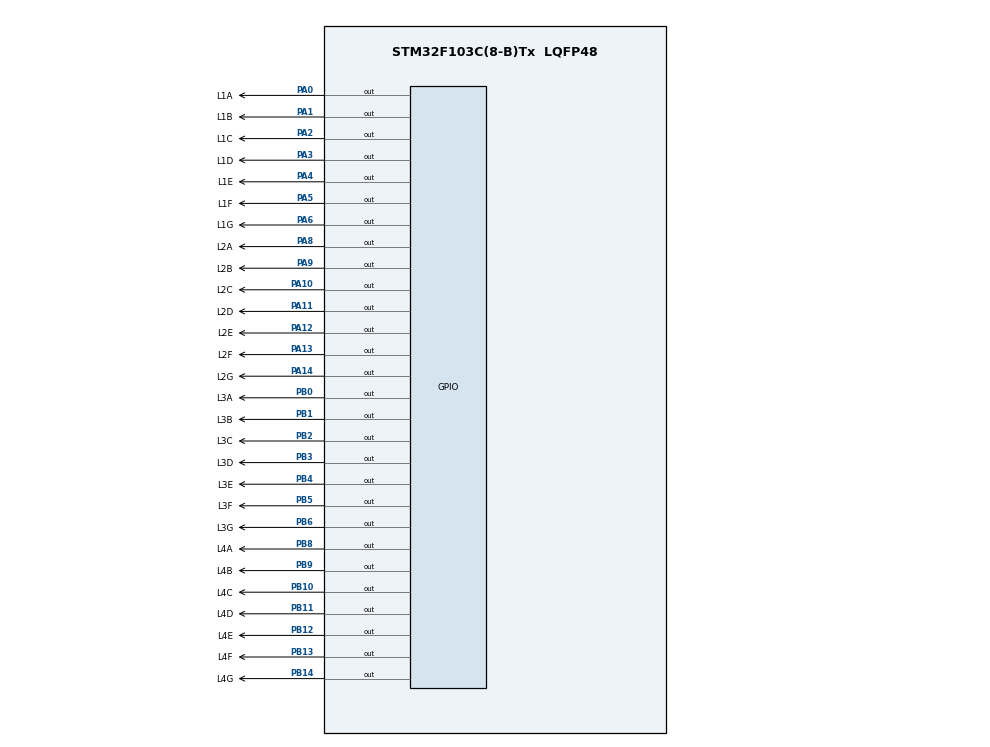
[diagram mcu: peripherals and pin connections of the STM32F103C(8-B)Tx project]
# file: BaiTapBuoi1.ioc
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Mcu.Family=STM32F1
Mcu.Name=STM32F103C(8-B)Tx
Mcu.Package=LQFP48
NVIC.PriorityGroup=NVIC_PRIORITYGROUP_4
PA0-WKUP.GPIO_Label=L1A
PA0-WKUP.Signal=GPIO_Output
PA1.GPIO_Label=L1B
PA1.Signal=GPIO_Output
PA10.GPIO_Label=L2C
PA10.Signal=GPIO_Output
PA11.GPIO_Label=L2D
PA11.Signal=GPIO_Output
PA12.GPIO_Label=L2E
PA12.Signal=GPIO_Output
PA13.GPIO_Label=L2F
PA13.Signal=GPIO_Output
PA14.GPIO_Label=L2G
PA14.Signal=GPIO_Output
PA2.GPIO_Label=L1C
PA2.Signal=GPIO_Output
PA3.GPIO_Label=L1D
PA3.Signal=GPIO_Output
PA4.GPIO_Label=L1E
PA4.Signal=GPIO_Output
PA5.GPIO_Label=L1F
PA5.Signal=GPIO_Output
PA6.GPIO_Label=L1G
PA6.Signal=GPIO_Output
PA8.GPIO_Label=L2A
PA8.Signal=GPIO_Output
PA9.GPIO_Label=L2B
PA9.Signal=GPIO_Output
PB0.GPIO_Label=L3A
PB0.Signal=GPIO_Output
PB1.GPIO_Label=L3B
PB1.Signal=GPIO_Output
PB10.GPIO_Label=L4C
PB10.Signal=GPIO_Output
PB11.GPIO_Label=L4D
PB11.Signal=GPIO_Output
PB12.GPIO_Label=L4E
PB12.Signal=GPIO_Output
PB13.GPIO_Label=L4F
PB13.Signal=GPIO_Output
PB14.GPIO_Label=L4G
PB14.Signal=GPIO_Output
PB2.GPIO_Label=L3C
PB2.Signal=GPIO_Output
PB3.GPIO_Label=L3D
PB3.Signal=GPIO_Output
PB4.GPIO_Label=L3E
PB4.Signal=GPIO_Output
PB5.GPIO_Label=L3F
PB5.Signal=GPIO_Output
PB6.GPIO_Label=L3G
PB6.Signal=GPIO_Output
PB8.GPIO_Label=L4A
PB8.Signal=GPIO_Output
PB9.GPIO_Label=L4B
PB9.Signal=GPIO_Output
ProjectManager.HeapSize=0x200
ProjectManager.StackSize=0x400
ProjectManager.TargetToolchain=MDK-ARM V5.32
RCC.APB1Freq_Value=8000000
RCC.APB2Freq_Value=8000000
VP_SYS_VS_ND.Mode=No_Debug
board=custom

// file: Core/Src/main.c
/* USER CODE BEGIN Header */
/**
  ******************************************************************************
  * @file           : main.c
  * @brief          : Main program body
  ******************************************************************************
  * @attention
  *
  * Copyright (c) 2025 STMicroelectronics.
  * All rights reserved.
  *
  * This software is licensed under terms that can be found in the LICENSE file
  * in the root directory of this software component.
  * If no LICENSE file comes with this software, it is provided AS-IS.
  *
  ******************************************************************************
  */
/* USER CODE END Header */
#include "main.h"

/* USER CODE BEGIN Includes */
#include "myLED.h"
/* USER CODE END Includes */

/* USER CODE BEGIN PV */

uint16_t num = 0;

/* USER CODE END PV */

void SystemClock_Config(void);
static void MX_GPIO_Init(void);

int main(void)
{

  /* MCU Configuration--------------------------------------------------------*/

  /* Reset of all peripherals, Initializes the Flash interface and the Systick. */
  HAL_Init();

  /* Configure the system clock */
  SystemClock_Config();

  /* Initialize all configured peripherals */
  MX_GPIO_Init();

  /* Infinite loop */
  /* USER CODE BEGIN WHILE */
  while (1)
  {
		LED_display(num);
		HAL_Delay(300);
		if(++num == 10000)
		{
			num = 0;
		}
    /* USER CODE END WHILE */

  }
}

void SystemClock_Config(void)
{
  RCC_OscInitTypeDef RCC_OscInitStruct = {0};
  RCC_ClkInitTypeDef RCC_ClkInitStruct = {0};

  /** Initializes the RCC Oscillators according to the specified parameters
  * in the RCC_OscInitTypeDef structure.
  */
  RCC_OscInitStruct.OscillatorType = RCC_OSCILLATORTYPE_HSI;
  RCC_OscInitStruct.HSIState = RCC_HSI_ON;
  RCC_OscInitStruct.HSICalibrationValue = RCC_HSICALIBRATION_DEFAULT;
  RCC_OscInitStruct.PLL.PLLState = RCC_PLL_NONE;
  if (HAL_RCC_OscConfig(&RCC_OscInitStruct) != HAL_OK)
  {
    Error_Handler();
  }

  /** Initializes the CPU, AHB and APB buses clocks
  */
  RCC_ClkInitStruct.ClockType = RCC_CLOCKTYPE_HCLK|RCC_CLOCKTYPE_SYSCLK
                              |RCC_CLOCKTYPE_PCLK1|RCC_CLOCKTYPE_PCLK2;
  RCC_ClkInitStruct.SYSCLKSource = RCC_SYSCLKSOURCE_HSI;
  RCC_ClkInitStruct.AHBCLKDivider = RCC_SYSCLK_DIV1;
  RCC_ClkInitStruct.APB1CLKDivider = RCC_HCLK_DIV1;
  RCC_ClkInitStruct.APB2CLKDivider = RCC_HCLK_DIV1;

  if (HAL_RCC_ClockConfig(&RCC_ClkInitStruct, FLASH_LATENCY_0) != HAL_OK)
  {
    Error_Handler();
  }
}

static void MX_GPIO_Init(void)
{
  GPIO_InitTypeDef GPIO_InitStruct = {0};

  /* GPIO Ports Clock Enable */
  __HAL_RCC_GPIOA_CLK_ENABLE();
  __HAL_RCC_GPIOB_CLK_ENABLE();

  /*Configure GPIO pin Output Level */
  HAL_GPIO_WritePin(GPIOA, L1A_Pin|L1B_Pin|L1C_Pin|L1D_Pin
                          |L1E_Pin|L1F_Pin|L1G_Pin|L2A_Pin
                          |L2B_Pin|L2C_Pin|L2D_Pin|L2E_Pin
                          |L2F_Pin|L2G_Pin, GPIO_PIN_RESET);

  /*Configure GPIO pin Output Level */
  HAL_GPIO_WritePin(GPIOB, L3A_Pin|L3B_Pin|L3C_Pin|L4C_Pin
                          |L4D_Pin|L4E_Pin|L4F_Pin|L4G_Pin
                          |L3D_Pin|L3E_Pin|L3F_Pin|L3G_Pin
                          |L4A_Pin|L4B_Pin, GPIO_PIN_RESET);

  /*Configure GPIO pins : L1A_Pin L1B_Pin L1C_Pin L1D_Pin
                           L1E_Pin L1F_Pin L1G_Pin L2A_Pin
                           L2B_Pin L2C_Pin L2D_Pin L2E_Pin
                           L2F_Pin L2G_Pin */
  GPIO_InitStruct.Pin = L1A_Pin|L1B_Pin|L1C_Pin|L1D_Pin
                          |L1E_Pin|L1F_Pin|L1G_Pin|L2A_Pin
                          |L2B_Pin|L2C_Pin|L2D_Pin|L2E_Pin
                          |L2F_Pin|L2G_Pin;
  GPIO_InitStruct.Mode = GPIO_MODE_OUTPUT_PP;
  GPIO_InitStruct.Pull = GPIO_NOPULL;
  GPIO_InitStruct.Speed = GPIO_SPEED_FREQ_LOW;
  HAL_GPIO_Init(GPIOA, &GPIO_InitStruct);

  /*Configure GPIO pins : L3A_Pin L3B_Pin L3C_Pin L4C_Pin
                           L4D_Pin L4E_Pin L4F_Pin L4G_Pin
                           L3D_Pin L3E_Pin L3F_Pin L3G_Pin
                           L4A_Pin L4B_Pin */
  GPIO_InitStruct.Pin = L3A_Pin|L3B_Pin|L3C_Pin|L4C_Pin
                          |L4D_Pin|L4E_Pin|L4F_Pin|L4G_Pin
                          |L3D_Pin|L3E_Pin|L3F_Pin|L3G_Pin
                          |L4A_Pin|L4B_Pin;
  GPIO_InitStruct.Mode = GPIO_MODE_OUTPUT_PP;
  GPIO_InitStruct.Pull = GPIO_NOPULL;
  GPIO_InitStruct.Speed = GPIO_SPEED_FREQ_LOW;
  HAL_GPIO_Init(GPIOB, &GPIO_InitStruct);

}

void Error_Handler(void)
{
  __disable_irq();
  while (1)
  {
  }
}
